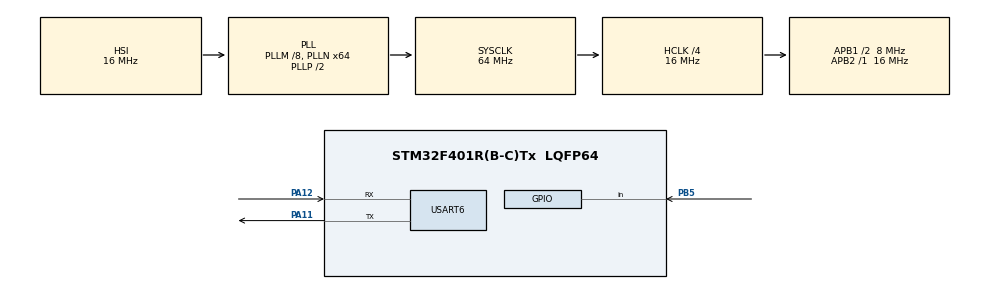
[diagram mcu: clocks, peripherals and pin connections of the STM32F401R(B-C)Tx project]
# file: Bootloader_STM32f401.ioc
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Mcu.Family=STM32F4
Mcu.Name=STM32F401R(B-C)Tx
Mcu.Package=LQFP64
NVIC.PriorityGroup=NVIC_PRIORITYGROUP_4
PA11.Mode=Asynchronous
PA11.Signal=USART6_TX
PA12.Mode=Asynchronous
PA12.Signal=USART6_RX
PA13.Mode=Serial_Wire
PA13.Signal=SYS_JTMS-SWDIO
PA14.Mode=Serial_Wire
PA14.Signal=SYS_JTCK-SWCLK
PB5.Signal=GPIO_Input
ProjectManager.HeapSize=0x200
ProjectManager.StackSize=0x400
ProjectManager.TargetToolchain=STM32CubeIDE
RCC.48MHZClocksFreq_Value=32000000
RCC.AHBCLKDivider=RCC_SYSCLK_DIV4
RCC.AHBFreq_Value=16000000
RCC.APB1CLKDivider=RCC_HCLK_DIV2
RCC.APB1Freq_Value=8000000
RCC.APB1TimFreq_Value=16000000
RCC.APB2Freq_Value=16000000
RCC.APB2TimFreq_Value=16000000
RCC.CortexFreq_Value=16000000
RCC.HCLKFreq_Value=16000000
RCC.HSE_VALUE=25000000
RCC.HSI_VALUE=16000000
RCC.LSE_VALUE=32768
RCC.PLLM=8
RCC.PLLN=64
RCC.SYSCLKFreq_VALUE=64000000
RCC.SYSCLKSource=RCC_SYSCLKSOURCE_PLLCLK
RCC.VCOOutputFreq_Value=128000000
USART6.VirtualMode=VM_ASYNC
VP_CRC_VS_CRC.Mode=CRC_Activate
board=custom

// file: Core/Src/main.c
/* USER CODE BEGIN Header */
/**
  ******************************************************************************
  * @file           : main.c
  * @brief          : Main program body
  ******************************************************************************
  * @attention
  *
  * Copyright (c) 2025 STMicroelectronics.
  * All rights reserved.
  *
  * This software is licensed under terms that can be found in the LICENSE file
  * in the root directory of this software component.
  * If no LICENSE file comes with this software, it is provided AS-IS.
  *
  ******************************************************************************
  */
/* USER CODE END Header */
#include "main.h"

CRC_HandleTypeDef hcrc;

UART_HandleTypeDef huart6;

void SystemClock_Config(void);
static void MX_GPIO_Init(void);
static void MX_CRC_Init(void);
static void MX_USART6_UART_Init(void);
/* USER CODE BEGIN PFP */
void Bootloader_UartReadData(void);
void Bootloader_JumpToUserAPP(void);
/* USER CODE END PFP */

int main(void)
{

  /* USER CODE BEGIN 1 */
	uint8_t HellowBootloade[] = "Bootloader is Run \r\n";
  /* USER CODE END 1 */

  /* MCU Configuration--------------------------------------------------------*/

  /* Reset of all peripherals, Initializes the Flash interface and the Systick. */
  HAL_Init();

  /* Configure the system clock */
  SystemClock_Config();

  /* Initialize all configured peripherals */
  MX_GPIO_Init();
  MX_CRC_Init();
  MX_USART6_UART_Init();
  /* USER CODE BEGIN 2 */

    GPIO_PinState PinVal;
	PinVal = HAL_GPIO_ReadPin(GPIOB, GPIO_PIN_5);
	if(PinVal == GPIO_PIN_SET)
	{
		Bootloader_UartReadData();
	}
	else
	{
		Bootloader_JumpToUserAPP();
	}

  /* USER CODE END 2 */

  /* Infinite loop */
  while (1)
  {

    /* USER CODE BEGIN 3 */

	    /* Transmit data */
	  HAL_UART_Transmit(&huart6, HellowBootloade, sizeof(HellowBootloade),HAL_MAX_DELAY);
  }
  /* USER CODE END 3 */
}

void SystemClock_Config(void)
{
  RCC_OscInitTypeDef RCC_OscInitStruct = {0};
  RCC_ClkInitTypeDef RCC_ClkInitStruct = {0};

  /** Configure the main internal regulator output voltage
  */
  __HAL_RCC_PWR_CLK_ENABLE();
  __HAL_PWR_VOLTAGESCALING_CONFIG(PWR_REGULATOR_VOLTAGE_SCALE2);

  /** Initializes the RCC Oscillators according to the specified parameters
  * in the RCC_OscInitTypeDef structure.
  */
  RCC_OscInitStruct.OscillatorType = RCC_OSCILLATORTYPE_HSI;
  RCC_OscInitStruct.HSIState = RCC_HSI_ON;
  RCC_OscInitStruct.HSICalibrationValue = RCC_HSICALIBRATION_DEFAULT;
  RCC_OscInitStruct.PLL.PLLState = RCC_PLL_ON;
  RCC_OscInitStruct.PLL.PLLSource = RCC_PLLSOURCE_HSI;
  RCC_OscInitStruct.PLL.PLLM = 8;
  RCC_OscInitStruct.PLL.PLLN = 64;
  RCC_OscInitStruct.PLL.PLLP = RCC_PLLP_DIV2;
  RCC_OscInitStruct.PLL.PLLQ = 4;
  if (HAL_RCC_OscConfig(&RCC_OscInitStruct) != HAL_OK)
  {
    Error_Handler();
  }

  /** Initializes the CPU, AHB and APB buses clocks
  */
  RCC_ClkInitStruct.ClockType = RCC_CLOCKTYPE_HCLK|RCC_CLOCKTYPE_SYSCLK
                              |RCC_CLOCKTYPE_PCLK1|RCC_CLOCKTYPE_PCLK2;
  RCC_ClkInitStruct.SYSCLKSource = RCC_SYSCLKSOURCE_PLLCLK;
  RCC_ClkInitStruct.AHBCLKDivider = RCC_SYSCLK_DIV4;
  RCC_ClkInitStruct.APB1CLKDivider = RCC_HCLK_DIV2;
  RCC_ClkInitStruct.APB2CLKDivider = RCC_HCLK_DIV1;

  if (HAL_RCC_ClockConfig(&RCC_ClkInitStruct, FLASH_LATENCY_0) != HAL_OK)
  {
    Error_Handler();
  }
}

static void MX_CRC_Init(void)
{

  hcrc.Instance = CRC;
  if (HAL_CRC_Init(&hcrc) != HAL_OK)
  {
    Error_Handler();
  }

}

static void MX_USART6_UART_Init(void)
{

  huart6.Instance = USART6;
  huart6.Init.BaudRate = 115200;
  huart6.Init.WordLength = UART_WORDLENGTH_8B;
  huart6.Init.StopBits = UART_STOPBITS_1;
  huart6.Init.Parity = UART_PARITY_NONE;
  huart6.Init.Mode = UART_MODE_TX_RX;
  huart6.Init.HwFlowCtl = UART_HWCONTROL_NONE;
  huart6.Init.OverSampling = UART_OVERSAMPLING_16;
  if (HAL_UART_Init(&huart6) != HAL_OK)
  {
    Error_Handler();
  }

}

static void MX_GPIO_Init(void)
{
  GPIO_InitTypeDef GPIO_InitStruct = {0};

  /* GPIO Ports Clock Enable */
  __HAL_RCC_GPIOA_CLK_ENABLE();
  __HAL_RCC_GPIOB_CLK_ENABLE();

  /*Configure GPIO pin : PB5 */
  GPIO_InitStruct.Pin = GPIO_PIN_5;
  GPIO_InitStruct.Mode = GPIO_MODE_INPUT;
  GPIO_InitStruct.Pull = GPIO_NOPULL;
  HAL_GPIO_Init(GPIOB, &GPIO_InitStruct);

}

void Error_Handler(void)
{
  __disable_irq();
  while (1)
  {
  }
}
